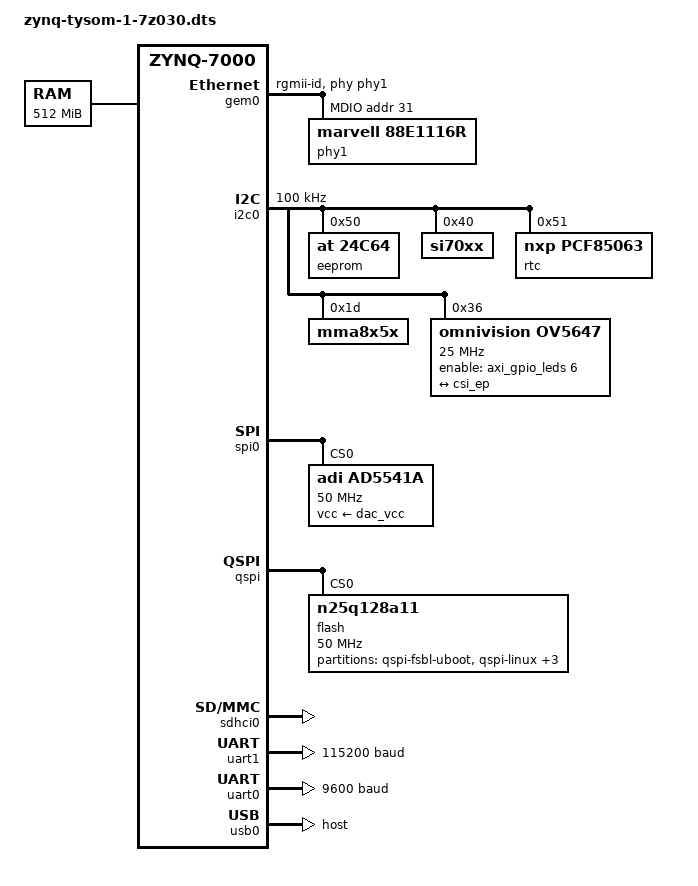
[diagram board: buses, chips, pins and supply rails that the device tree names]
/*
 * CAUTION: This file is automatically generated by Xilinx.
 * Version:  
 * Today is: Thu Jul  9 10:42:48 2015
*/


/dts-v1/;
/include/ "zynq-7000.dtsi"
/include/ "pl.dtsi"
/ {
	cpus {
		cpu@0 {
			operating-points = <650000 1000000 325000 1000000>;
		};
	};
	chosen {
		bootargs = "console=ttyPS0,115200 root=/dev/mmcblk0p2 rw earlyprintk rootfstype=ext4 rootwait";
	};
	aliases {
		ethernet0 = &gem0;
		serial0 = &uart1;
		serial1 = &uart0;
		qspi0 = &qspi;
		spi = &spi0;
	};
	memory {
		device_type = "memory";
		reg = <0x0 0x20000000>;
	};
};
&gem0 {
	enet-reset = <&gpio0 51 0>;
	local-mac-address = [00 0a 35 00 00 00];
	phy-handle = <&phy1>;
	phy-mode = "rgmii-id";
	status = "okay";
	xlnx,ptp-enet-clock = <0x6750918>;
	ps7_ethernet_0_mdio: mdio {
		#address-cells = <1>;
		#size-cells = <0>;
		phy1: phy@1f {
		    compatible = "marvell,88e1116r";
		    device_type = "ethernet-phy";
		    reg = <0x1f>;
		};
	};
};
&gpio0 {
	emio-gpio-width = <64>;
	gpio-mask-high = <0x0>;
	gpio-mask-low = <0x5600>;
};
&intc {
	num_cpus = <2>;
	num_interrupts = <96>;
};

&i2c0 {
	status = "okay";
	clock-frequency = <100000>;
	
	eeprom@50 {
                compatible = "at,24c64";
                reg = <0x50>;
        };
	
	si70xx: si70xx@40 {
                compatible = "si70xx";
                reg = <0x40>;
        };
	
	rtc@51 {
                compatible = "nxp,pcf85063";
                reg = <0x51>;
        };
	
	mma8x5x: mma8x5x@1d {
                compatible = "mma8x5x";
                reg = <0x1d>;
		/*interrupt-parent = <&intc>;
		interrupts = <0 55 8>, <0 54 8>;*/
        };
	
	ov5647: ov5647@36 {
	      compatible = "omnivision,ov5647";
	      reg = <0x36>;

	      clock-frequency = <25000000>;

	      enable-gpios = <&axi_gpio_leds 6 0>;

	      port {
		      ov5647_ep: endpoint {
			      remote-endpoint = <&csi_ep>;
			      clock-lanes = <0>;
			      data-lanes = <1 2>;
		      };
	      };
	};
};

&spi0 {
	status = "okay";
	num-cs = <4>;
	is-decoded-cs = <0>;	
	
	ad5541a@0 {
	      compatible = "adi,ad5541a";
	      reg = <0x0>;
	      spi-max-frequency = <50000000>;
	      spi-cpha;
	      spi-cpol;
	      vcc-supply = <&dac_vcc>;
	};
};

&qspi {
	status = "okay";
	is-dual = <0>;
	num-cs = <1>;
	
	flash@0 {
              compatible = "n25q128a11";
              reg = <0x0>;
              spi-tx-bus-width = <1>;
              spi-rx-bus-width = <4>;
              spi-max-frequency = <50000000>;
              #address-cells = <1>;
              #size-cells = <1>;
              partition@qspi-fsbl-uboot {
                        label = "qspi-fsbl-uboot";
                        reg = <0x0 0x100000>;
              };
              partition@qspi-linux {
                        label = "qspi-linux";
                        reg = <0x100000 0x500000>;
              };
              partition@qspi-device-tree {
                        label = "qspi-device-tree";
                        reg = <0x600000 0x20000>;
              };
              partition@qspi-rootfs {
                        label = "qspi-rootfs";
                        reg = <0x620000 0x5E0000>;
              };
              partition@qspi-bitstream {
                        label = "qspi-bitstream";
                        reg = <0xC00000 0x400000>;
              };
      };
};

&sdhci0 {
	clock-frequency = <50000000>;
	status = "okay";
};
&uart1 {
	current-speed = <115200>;
	device_type = "serial";
	port-number = <0>;
	status = "okay";
};
&uart0 {
	current-speed = <9600>;
	device_type = "serial";
	port-number = <1>;
	status = "okay";
};
&usb0 {
	phy_type = "ulpi";
	dr_mode = "host";
	status = "okay";
	usb-reset = <&gpio0 9 0>;
};
&clkc {
	fclk-enable = <0x7>; /* enable fclocks 1,2,3 */
	ps-clk-frequency = <50000000>;
};
